CM_ "AUTOGENERATED FILE, DO NOT EDIT";

CM_ "Imported file _wuling_almazrs.dbc starts here";
VERSION ""

NS_ :

BS_:

BU_:

BO_ 840 EBCMWheelSpdFront: 4 K17_EBCM
 SG_ FLWheelSpd : 7|16@0+ (0.0311,0) [0|255] "km/h"  NEO
 SG_ FRWheelSpd : 23|16@0+ (0.0311,0) [0|255] "km/h"  NEO

BO_ 842 EBCMWheelSpdRear: 5 K17_EBCM
 SG_ RLWheelSpd : 7|16@0+ (0.0311,0) [0|255] "km/h"  NEO
 SG_ RRWheelSpd : 23|16@0+ (0.0311,0) [0|255] "km/h"  NEO

BO_ 485 PSCMSteeringAngle: 8 K43_PSCM
 SG_ SteeringWheelAngle : 15|16@0- (0.0625,0) [-2047|2047] "deg"  NEO
 SG_ SteeringWheelRate : 27|12@0- (1,0) [-2047|2047] "deg/s"  NEO

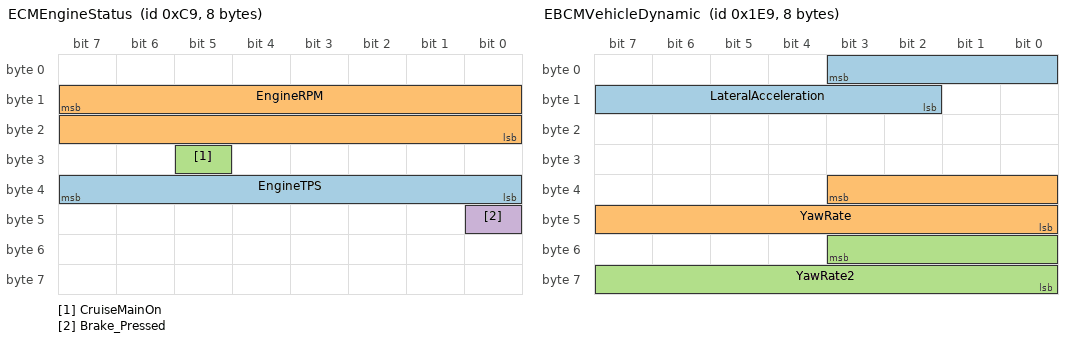
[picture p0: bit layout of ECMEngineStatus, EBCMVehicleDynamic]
BO_ 201 ECMEngineStatus: 8 K20_ECM
 SG_ EngineTPS : 39|8@0+ (0.392156863,0) [0|100.000000065] "%" NEO
 SG_ EngineRPM : 15|16@0+ (0.25,0) [0|0] "RPM" NEO
 SG_ CruiseMainOn : 29|1@0+ (1,0) [0|1] "" NEO
 SG_ Brake_Pressed : 40|1@0+ (1,0) [0|1] "" NEO

BO_ 489 EBCMVehicleDynamic: 8 K17_EBCM
 SG_ LateralAcceleration : 3|10@0- (0.161,0) [-2047|2047] "m/s2" NEO
 SG_ YawRate : 35|12@0- (0.625,0) [0|1] "" NEO
 SG_ YawRate2 : 51|12@0- (0.0625,0) [-2047|2047] "grad/s" NEO

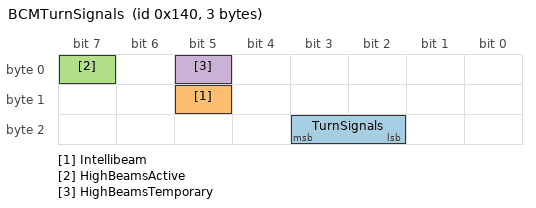
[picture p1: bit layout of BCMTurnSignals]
BO_ 320 BCMTurnSignals: 3 K9_BCM
 SG_ TurnSignals : 19|2@0+ (1,0) [0|0] ""  NEO
 SG_ Intellibeam : 13|1@0+ (1,0) [0|1] "" XXX
 SG_ HighBeamsActive : 7|1@0+ (1,0) [0|1] "" XXX
 SG_ HighBeamsTemporary : 5|1@0+ (1,0) [0|1] "" XXX

BO_ 298 BCMDoorBeltStatus: 8 K9_BCM
 SG_ FrontRightDoor : 16|1@0+ (1,0) [0|1] "" NEO
 SG_ RearRightDoor : 23|1@0+ (1,0) [0|0] "" NEO
 SG_ RightSeatBelt : 53|1@0+ (1,0) [0|0] "" NEO
 SG_ LeftSeatBelt : 12|1@0+ (1,0) [0|0] "" NEO
 SG_ FrontLeftDoor : 9|1@0+ (1,0) [0|0] "" NEO
 SG_ RearLeftDoor : 9|1@0+ (1,0) [0|0] "" NEO

BO_ 560 EPBStatus: 8 EPB
 SG_ EPBClosed : 12|1@0+ (1,0) [0|1] ""  NEO
 SG_ EPBSTATUS : 8|1@0+ (1,0) [0|1] "" XXX
